AUTOSAR XML (schema 00047)
package /ServiceApplTemplate/SwComponentTypes
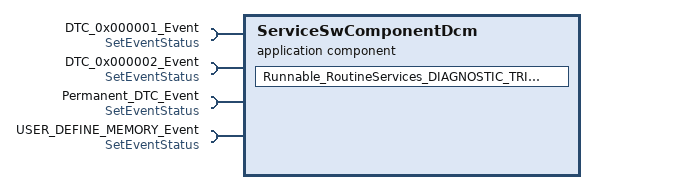
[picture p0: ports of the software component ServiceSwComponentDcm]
  application sw component type ServiceSwComponentDcm
    4 x require port, all with required-interface=SetEventStatus:
      DTC_0x000001_Event
      DTC_0x000002_Event
      Permanent_DTC_Event
      USER_DEFINE_MEMORY_Event
    behavior ServiceSwComponentDcm_IB: handle-termination-and-restart=NO-SUPPORT
      runnable Runnable_RoutineServices_DIAGNOSTIC_TRIGGER_DTC_A5663192471BAAA2C67D187118DC8330: symbol=ServiceSwComponentDcm_RoutineServices_DIAGNOSTIC_TRIGGER_DTC_Start
        4 x sync call, all with timeout=0.0:
          SetEventStatus_DTC_0x00002: operation=DTC_0x000002_Event.SetEventStatus
          SetEventStatus_DTC_0x000001: operation=DTC_0x000001_Event.SetEventStatus
          SetEventStatus_PermanentDTC: operation=Permanent_DTC_Event.SetEventStatus
          SetEventStatus_User_Memory: operation=USER_DEFINE_MEMORY_Event.SetEventStatus
package /DemoApplication/SwComponentTypes
  composition sw component type TopLevelComposition
    component ServiceSwComponentDcm: type=ServiceSwComponentDcm
    connect Dem_Prototype.Event_DTC_0x000001_Event -> ServiceSwComponentDcm.DTC_0x000001_Event
    connect Dem_Prototype.Event_Permanent_DTC -> ServiceSwComponentDcm.Permanent_DTC_Event
    connect Dem_Prototype.Event_DTC_0x000002_Event -> ServiceSwComponentDcm.DTC_0x000002_Event
    connect Dem_Prototype.Event_USER_DEFINE_MEMORY_Event -> ServiceSwComponentDcm.USER_DEFINE_MEMORY_Event
package /PortInterfaces
  client server interface SetEventStatus: is-service=true
    operation SetEventStatus: possible-error=[E_NOT_OK, E_OK]
      arg EventStatus: type=Dem_EventStatusType, direction=IN
    error E_NOT_OK: error-code=1
    error E_OK: error-code=0
package /CompuMethods
  compu method CM_EventStatusType: 0=DEM_EVENT_STATUS_PASSED, 1=DEM_EVENT_STATUS_FAILED, 2=DEM_EVENT_STATUS_PREPASSED, 3=DEM_EVENT_STATUS_PREFAILED
package /DataConstr
  range CONSTR_EventStatusType: raw 0..3
